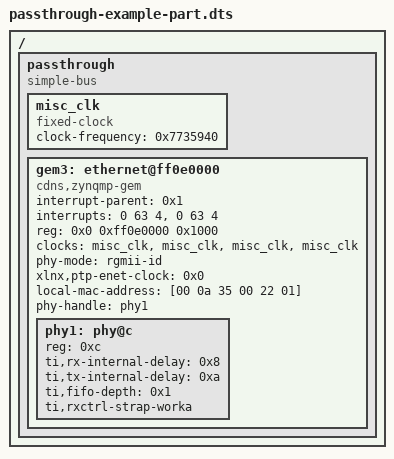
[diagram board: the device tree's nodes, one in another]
/dts-v1/;

/ {
	#address-cells = <0x2>;
	#size-cells = <0x1>;

	passthrough {
		compatible = "simple-bus";
		ranges;
		#address-cells = <0x2>;
		#size-cells = <0x1>;

		misc_clk: misc_clk {
			#clock-cells = <0x0>;
			clock-frequency = <0x7735940>;
			compatible = "fixed-clock";
		};

		gem3: ethernet@ff0e0000 {
			compatible = "cdns,zynqmp-gem";
			status = "okay";
			interrupt-parent = <0x1>;
			interrupts = <0 63 4>, <0 63 4>;
			reg = <0x0 0xff0e0000 0x1000>;
			clock-names = "pclk", "hclk", "tx_clk", "rx_clk";
			#address-cells = <1>;
			#size-cells = <0>;
			clocks = <&misc_clk &misc_clk &misc_clk &misc_clk>;
			phy-mode = "rgmii-id";
			xlnx,ptp-enet-clock = <0x0>;
			local-mac-address = [00 0a 35 00 22 01];
			phy-handle = <&phy1>;

			phy1: phy@c {
				reg = <0xc>;
				ti,rx-internal-delay = <0x8>;
				ti,tx-internal-delay = <0xa>;
				ti,fifo-depth = <0x1>;
				ti,rxctrl-strap-worka;
			};
		};
	};
};
